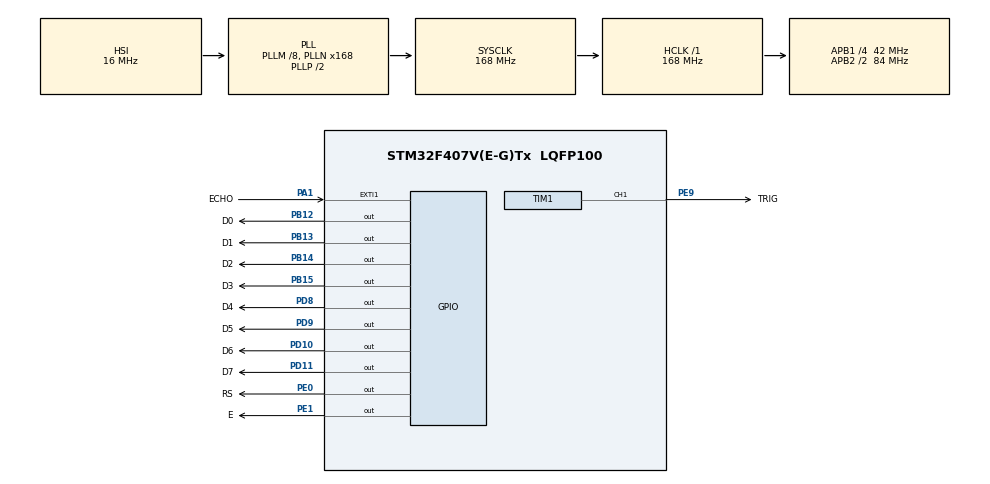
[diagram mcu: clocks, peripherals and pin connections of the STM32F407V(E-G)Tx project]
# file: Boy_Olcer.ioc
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Mcu.Family=STM32F4
Mcu.Name=STM32F407V(E-G)Tx
Mcu.Package=LQFP100
NVIC.EXTI1_IRQn=true\:0\:0\:false\:false\:true\:true\:true
NVIC.PriorityGroup=NVIC_PRIORITYGROUP_4
PA1.GPIO_Label=ECHO
PA1.GPIO_ModeDefaultEXTI=GPIO_MODE_IT_RISING_FALLING
PA1.Signal=GPXTI1
PB12.GPIO_Label=D0
PB12.Signal=GPIO_Output
PB13.GPIO_Label=D1
PB13.Signal=GPIO_Output
PB14.GPIO_Label=D2
PB14.Signal=GPIO_Output
PB15.GPIO_Label=D3
PB15.Signal=GPIO_Output
PD10.GPIO_Label=D6
PD10.Signal=GPIO_Output
PD11.GPIO_Label=D7
PD11.Signal=GPIO_Output
PD8.GPIO_Label=D4
PD8.Signal=GPIO_Output
PD9.GPIO_Label=D5
PD9.Signal=GPIO_Output
PE0.GPIO_Label=RS
PE0.Signal=GPIO_Output
PE1.GPIO_Label=E
PE1.Signal=GPIO_Output
PE9.GPIO_Label=TRIG
PE9.Signal=S_TIM1_CH1
ProjectManager.HeapSize=0x200
ProjectManager.StackSize=0x400
ProjectManager.TargetToolchain=MDK-ARM V5
RCC.48MHZClocksFreq_Value=84000000
RCC.AHBFreq_Value=168000000
RCC.APB1CLKDivider=RCC_HCLK_DIV4
RCC.APB1Freq_Value=42000000
RCC.APB1TimFreq_Value=84000000
RCC.APB2CLKDivider=RCC_HCLK_DIV2
RCC.APB2Freq_Value=84000000
RCC.APB2TimFreq_Value=168000000
RCC.CortexFreq_Value=168000000
RCC.HCLKFreq_Value=168000000
RCC.HSE_VALUE=25000000
RCC.HSI_VALUE=16000000
RCC.LSE_VALUE=32768
RCC.PLLM=8
RCC.PLLN=168
RCC.SYSCLKFreq_VALUE=168000000
RCC.SYSCLKSource=RCC_SYSCLKSOURCE_PLLCLK
RCC.VCOOutputFreq_Value=336000000
SH.S_TIM1_CH1.0=TIM1_CH1,PWM Generation1 CH1
TIM1.Channel-PWM\ Generation1\ CH1=TIM_CHANNEL_1
TIM1.Period=10000
TIM1.Prescaler=256
TIM1.Pulse-PWM\ Generation1\ CH1=100
board=custom

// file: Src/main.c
/* USER CODE BEGIN Header */
/**
  ******************************************************************************
  * @file           : main.c
  * @brief          : Main program body
  ******************************************************************************
  * @attention
  *
  * <h2><center>&copy; Copyright (c) 2019 STMicroelectronics.
  * All rights reserved.</center></h2>
  *
  * This software component is licensed by ST under BSD 3-Clause license,
  * the "License"; You may not use this file except in compliance with the
  * License. You may obtain a copy of the License at:
  *                        opensource.org/licenses/BSD-3-Clause
  *
  ******************************************************************************
  */
/* USER CODE END Header */

#include "main.h"

/* USER CODE BEGIN Includes */
#include "STM_MY_LCD16X2.h"

/* USER CODE END Includes */

TIM_HandleTypeDef htim1;

/* USER CODE BEGIN PV */
uint16_t s;
uint16_t s1;
uint16_t s2;
/* USER CODE END PV */

void SystemClock_Config(void);
static void MX_GPIO_Init(void);
static void MX_TIM1_Init(void);

int main(void)
{

  /* MCU Configuration--------------------------------------------------------*/

  /* Reset of all peripherals, Initializes the Flash interface and the Systick. */
  HAL_Init();

  /* Configure the system clock */
  SystemClock_Config();

  /* Initialize all configured peripherals */
  MX_GPIO_Init();
  MX_TIM1_Init();
  /* USER CODE BEGIN 2 */

	HAL_TIM_PWM_Start(&htim1, TIM_CHANNEL_1);
LCD1602_Begin8BIT(RS_GPIO_Port,RS_Pin,E_Pin,D0_GPIO_Port,D0_Pin,D1_Pin,D2_Pin,D3_Pin,D4_GPIO_Port,D4_Pin,D5_Pin,D6_Pin,D7_Pin);

/*LCD1602_print("Herkese");
LCD1602_2ndLine();
LCD1602_print("Merhaba");
HAL_Delay(1000);
LCD1602_clear();
LCD1602_noCursor();*/

  /* USER CODE END 2 */

  /* Infinite loop */
  /* USER CODE BEGIN WHILE */
  while (1)
  {
		LCD1602_1stLine();
		LCD1602_print("Boyunuz:");
		LCD1602_PrintInt(s);
		LCD1602_print(" cm");
		//HAL_Delay(100);

    /* USER CODE END WHILE */

  }
}

void SystemClock_Config(void)
{
  RCC_OscInitTypeDef RCC_OscInitStruct = {0};
  RCC_ClkInitTypeDef RCC_ClkInitStruct = {0};

  /** Configure the main internal regulator output voltage
  */
  __HAL_RCC_PWR_CLK_ENABLE();
  __HAL_PWR_VOLTAGESCALING_CONFIG(PWR_REGULATOR_VOLTAGE_SCALE1);
  /** Initializes the CPU, AHB and APB busses clocks
  */
  RCC_OscInitStruct.OscillatorType = RCC_OSCILLATORTYPE_HSI;
  RCC_OscInitStruct.HSIState = RCC_HSI_ON;
  RCC_OscInitStruct.HSICalibrationValue = RCC_HSICALIBRATION_DEFAULT;
  RCC_OscInitStruct.PLL.PLLState = RCC_PLL_ON;
  RCC_OscInitStruct.PLL.PLLSource = RCC_PLLSOURCE_HSI;
  RCC_OscInitStruct.PLL.PLLM = 8;
  RCC_OscInitStruct.PLL.PLLN = 168;
  RCC_OscInitStruct.PLL.PLLP = RCC_PLLP_DIV2;
  RCC_OscInitStruct.PLL.PLLQ = 4;
  if (HAL_RCC_OscConfig(&RCC_OscInitStruct) != HAL_OK)
  {
    Error_Handler();
  }
  /** Initializes the CPU, AHB and APB busses clocks
  */
  RCC_ClkInitStruct.ClockType = RCC_CLOCKTYPE_HCLK|RCC_CLOCKTYPE_SYSCLK
                              |RCC_CLOCKTYPE_PCLK1|RCC_CLOCKTYPE_PCLK2;
  RCC_ClkInitStruct.SYSCLKSource = RCC_SYSCLKSOURCE_PLLCLK;
  RCC_ClkInitStruct.AHBCLKDivider = RCC_SYSCLK_DIV1;
  RCC_ClkInitStruct.APB1CLKDivider = RCC_HCLK_DIV4;
  RCC_ClkInitStruct.APB2CLKDivider = RCC_HCLK_DIV2;

  if (HAL_RCC_ClockConfig(&RCC_ClkInitStruct, FLASH_LATENCY_5) != HAL_OK)
  {
    Error_Handler();
  }
}

static void MX_TIM1_Init(void)
{

  TIM_MasterConfigTypeDef sMasterConfig = {0};
  TIM_OC_InitTypeDef sConfigOC = {0};
  TIM_BreakDeadTimeConfigTypeDef sBreakDeadTimeConfig = {0};

  htim1.Instance = TIM1;
  htim1.Init.Prescaler = 256;
  htim1.Init.CounterMode = TIM_COUNTERMODE_UP;
  htim1.Init.Period = 10000;
  htim1.Init.ClockDivision = TIM_CLOCKDIVISION_DIV1;
  htim1.Init.RepetitionCounter = 0;
  htim1.Init.AutoReloadPreload = TIM_AUTORELOAD_PRELOAD_DISABLE;
  if (HAL_TIM_PWM_Init(&htim1) != HAL_OK)
  {
    Error_Handler();
  }
  sMasterConfig.MasterOutputTrigger = TIM_TRGO_RESET;
  sMasterConfig.MasterSlaveMode = TIM_MASTERSLAVEMODE_DISABLE;
  if (HAL_TIMEx_MasterConfigSynchronization(&htim1, &sMasterConfig) != HAL_OK)
  {
    Error_Handler();
  }
  sConfigOC.OCMode = TIM_OCMODE_PWM1;
  sConfigOC.Pulse = 100;
  sConfigOC.OCPolarity = TIM_OCPOLARITY_HIGH;
  sConfigOC.OCNPolarity = TIM_OCNPOLARITY_HIGH;
  sConfigOC.OCFastMode = TIM_OCFAST_DISABLE;
  sConfigOC.OCIdleState = TIM_OCIDLESTATE_RESET;
  sConfigOC.OCNIdleState = TIM_OCNIDLESTATE_RESET;
  if (HAL_TIM_PWM_ConfigChannel(&htim1, &sConfigOC, TIM_CHANNEL_1) != HAL_OK)
  {
    Error_Handler();
  }
  sBreakDeadTimeConfig.OffStateRunMode = TIM_OSSR_DISABLE;
  sBreakDeadTimeConfig.OffStateIDLEMode = TIM_OSSI_DISABLE;
  sBreakDeadTimeConfig.LockLevel = TIM_LOCKLEVEL_OFF;
  sBreakDeadTimeConfig.DeadTime = 0;
  sBreakDeadTimeConfig.BreakState = TIM_BREAK_DISABLE;
  sBreakDeadTimeConfig.BreakPolarity = TIM_BREAKPOLARITY_HIGH;
  sBreakDeadTimeConfig.AutomaticOutput = TIM_AUTOMATICOUTPUT_DISABLE;
  if (HAL_TIMEx_ConfigBreakDeadTime(&htim1, &sBreakDeadTimeConfig) != HAL_OK)
  {
    Error_Handler();
  }
  HAL_TIM_MspPostInit(&htim1);

}

static void MX_GPIO_Init(void)
{
  GPIO_InitTypeDef GPIO_InitStruct = {0};

  /* GPIO Ports Clock Enable */
  __HAL_RCC_GPIOA_CLK_ENABLE();
  __HAL_RCC_GPIOE_CLK_ENABLE();
  __HAL_RCC_GPIOB_CLK_ENABLE();
  __HAL_RCC_GPIOD_CLK_ENABLE();

  /*Configure GPIO pin Output Level */
  HAL_GPIO_WritePin(GPIOB, D0_Pin|D1_Pin|D2_Pin|D3_Pin, GPIO_PIN_RESET);

  /*Configure GPIO pin Output Level */
  HAL_GPIO_WritePin(GPIOD, D4_Pin|D5_Pin|D6_Pin|D7_Pin, GPIO_PIN_RESET);

  /*Configure GPIO pin Output Level */
  HAL_GPIO_WritePin(GPIOE, RS_Pin|E_Pin, GPIO_PIN_RESET);

  /*Configure GPIO pin : ECHO_Pin */
  GPIO_InitStruct.Pin = ECHO_Pin;
  GPIO_InitStruct.Mode = GPIO_MODE_IT_RISING_FALLING;
  GPIO_InitStruct.Pull = GPIO_NOPULL;
  HAL_GPIO_Init(ECHO_GPIO_Port, &GPIO_InitStruct);

  /*Configure GPIO pins : D0_Pin D1_Pin D2_Pin D3_Pin */
  GPIO_InitStruct.Pin = D0_Pin|D1_Pin|D2_Pin|D3_Pin;
  GPIO_InitStruct.Mode = GPIO_MODE_OUTPUT_PP;
  GPIO_InitStruct.Pull = GPIO_NOPULL;
  GPIO_InitStruct.Speed = GPIO_SPEED_FREQ_LOW;
  HAL_GPIO_Init(GPIOB, &GPIO_InitStruct);

  /*Configure GPIO pins : D4_Pin D5_Pin D6_Pin D7_Pin */
  GPIO_InitStruct.Pin = D4_Pin|D5_Pin|D6_Pin|D7_Pin;
  GPIO_InitStruct.Mode = GPIO_MODE_OUTPUT_PP;
  GPIO_InitStruct.Pull = GPIO_NOPULL;
  GPIO_InitStruct.Speed = GPIO_SPEED_FREQ_LOW;
  HAL_GPIO_Init(GPIOD, &GPIO_InitStruct);

  /*Configure GPIO pins : RS_Pin E_Pin */
  GPIO_InitStruct.Pin = RS_Pin|E_Pin;
  GPIO_InitStruct.Mode = GPIO_MODE_OUTPUT_PP;
  GPIO_InitStruct.Pull = GPIO_NOPULL;
  GPIO_InitStruct.Speed = GPIO_SPEED_FREQ_LOW;
  HAL_GPIO_Init(GPIOE, &GPIO_InitStruct);

  /* EXTI interrupt init*/
  HAL_NVIC_SetPriority(EXTI1_IRQn, 0, 0);
  HAL_NVIC_EnableIRQ(EXTI1_IRQn);

}

void Error_Handler(void)
{
}

/************************ (C) COPYRIGHT STMicroelectronics *****END OF FILE****/
